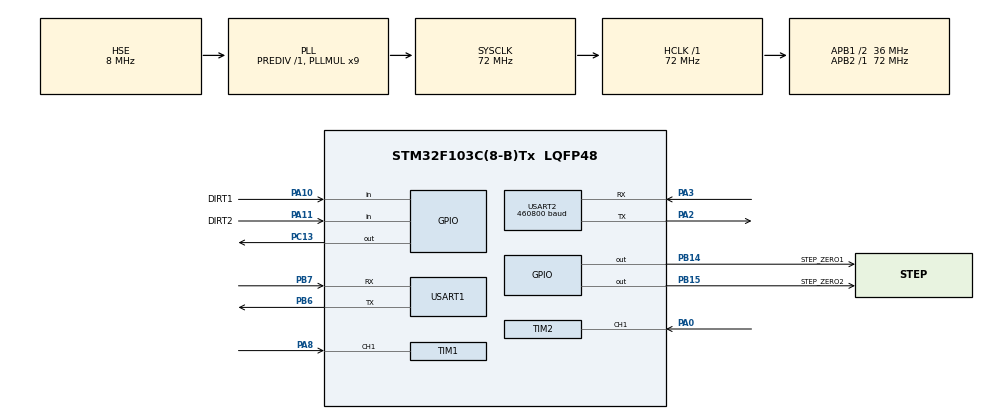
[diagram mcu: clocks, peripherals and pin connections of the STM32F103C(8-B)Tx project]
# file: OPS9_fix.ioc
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FREERTOS.Tasks01=defaultTask,24,128,StartDefaultTask,Default,NULL,Dynamic,NULL,NULL
FREERTOS.configENABLE_FPU=1
Mcu.Family=STM32F1
Mcu.Name=STM32F103C(8-B)Tx
Mcu.Package=LQFP48
NVIC.PriorityGroup=NVIC_PRIORITYGROUP_4
NVIC.TIM4_IRQn=true\:15\:0\:false\:false\:true\:false\:false\:true\:true
NVIC.TimeBase=TIM4_IRQn
NVIC.TimeBaseIP=TIM4
NVIC.USART1_IRQn=true\:5\:0\:false\:false\:true\:true\:true\:true\:true
NVIC.USART2_IRQn=true\:5\:0\:false\:false\:true\:true\:true\:true\:true
PA0-WKUP.Signal=S_TIM2_CH1_ETR
PA10.GPIO_Label=DIRT1
PA10.Signal=GPIO_Input
PA11.GPIO_Label=DIRT2
PA11.Signal=GPIO_Input
PA13.Mode=Serial_Wire
PA13.Signal=SYS_JTMS-SWDIO
PA14.Mode=Serial_Wire
PA14.Signal=SYS_JTCK-SWCLK
PA2.Mode=Asynchronous
PA2.Signal=USART2_TX
PA3.Mode=Asynchronous
PA3.Signal=USART2_RX
PA8.Signal=S_TIM1_CH1
PB14.GPIO_Label=STEP_ZERO1
PB14.Signal=GPIO_Output
PB15.GPIO_Label=STEP_ZERO2
PB15.Signal=GPIO_Output
PB6.Mode=Asynchronous
PB6.Signal=USART1_TX
PB7.Mode=Asynchronous
PB7.Signal=USART1_RX
PC13-TAMPER-RTC.Signal=GPIO_Output
PD0-OSC_IN.Mode=HSE-External-Oscillator
PD0-OSC_IN.Signal=RCC_OSC_IN
PD1-OSC_OUT.Mode=HSE-External-Oscillator
PD1-OSC_OUT.Signal=RCC_OSC_OUT
ProjectManager.HeapSize=0x200
ProjectManager.StackSize=0x400
ProjectManager.TargetToolchain=MDK-ARM V5.32
RCC.AHBFreq_Value=72000000
RCC.APB1CLKDivider=RCC_HCLK_DIV2
RCC.APB1Freq_Value=36000000
RCC.APB1TimFreq_Value=72000000
RCC.APB2Freq_Value=72000000
RCC.APB2TimFreq_Value=72000000
RCC.HCLKFreq_Value=72000000
RCC.PLLMUL=RCC_PLL_MUL9
RCC.PLLSourceVirtual=RCC_PLLSOURCE_HSE
RCC.SYSCLKFreq_VALUE=72000000
RCC.SYSCLKSource=RCC_SYSCLKSOURCE_PLLCLK
RCC.USBFreq_Value=72000000
SH.S_TIM1_CH1.0=TIM1_CH1,TriggerSource_TI1FP1
SH.S_TIM2_CH1_ETR.0=TIM2_CH1,TriggerSource_TI1FP1
USART1.VirtualMode=VM_ASYNC
USART2.BaudRate=460800
USART2.VirtualMode=VM_ASYNC
VP_FREERTOS_VS_CMSIS_V2.Mode=CMSIS_V2
VP_SYS_VS_tim4.Mode=TIM4
VP_TIM1_VS_ControllerModeClock.Mode=Clock Mode
VP_TIM2_VS_ControllerModeClock.Mode=Clock Mode
board=custom

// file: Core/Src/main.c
/* USER CODE BEGIN Header */
/**
  ******************************************************************************
  * @file           : main.c
  * @brief          : Main program body
  ******************************************************************************
  * @attention
  *
  * Copyright (c) 2026 STMicroelectronics.
  * All rights reserved.
  *
  * This software is licensed under terms that can be found in the LICENSE file
  * in the root directory of this software component.
  * If no LICENSE file comes with this software, it is provided AS-IS.
  *
  ******************************************************************************
  */
/* USER CODE END Header */
#include "main.h"
#include "cmsis_os.h"
#include "tim.h"
#include "usart.h"
#include "gpio.h"

/* USER CODE BEGIN Includes */
#include "cyz_gyro.h"
/* USER CODE END Includes */

void SystemClock_Config(void);
void MX_FREERTOS_Init(void);

int main(void)
{

  /* MCU Configuration--------------------------------------------------------*/

  /* Reset of all peripherals, Initializes the Flash interface and the Systick. */
  HAL_Init();

  /* Configure the system clock */
  SystemClock_Config();

  /* Initialize all configured peripherals */
  MX_GPIO_Init();
  MX_TIM1_Init();
  MX_TIM2_Init();
  MX_USART1_UART_Init();
  MX_USART2_UART_Init();
  /* USER CODE BEGIN 2 */
  /* QMM01/CY-Z gyro on USART1: bind the handle and arm byte-wise interrupt
     reception. Runs after MX_USART1_UART_Init() and before the scheduler
     starts, so the module is already reporting once the tasks run. */
  cyz_gyro_init();
  /* USER CODE END 2 */

  /* Init scheduler */
  osKernelInitialize();  /* Call init function for freertos objects (in cmsis_os2.c) */
  MX_FREERTOS_Init();

  /* Start scheduler */
  osKernelStart();

  /* We should never get here as control is now taken by the scheduler */

  /* Infinite loop */
  while (1)
  {

  }
}

void SystemClock_Config(void)
{
  RCC_OscInitTypeDef RCC_OscInitStruct = {0};
  RCC_ClkInitTypeDef RCC_ClkInitStruct = {0};

  /** Initializes the RCC Oscillators according to the specified parameters
  * in the RCC_OscInitTypeDef structure.
  */
  RCC_OscInitStruct.OscillatorType = RCC_OSCILLATORTYPE_HSE;
  RCC_OscInitStruct.HSEState = RCC_HSE_ON;
  RCC_OscInitStruct.HSEPredivValue = RCC_HSE_PREDIV_DIV1;
  RCC_OscInitStruct.HSIState = RCC_HSI_ON;
  RCC_OscInitStruct.PLL.PLLState = RCC_PLL_ON;
  RCC_OscInitStruct.PLL.PLLSource = RCC_PLLSOURCE_HSE;
  RCC_OscInitStruct.PLL.PLLMUL = RCC_PLL_MUL9;
  if (HAL_RCC_OscConfig(&RCC_OscInitStruct) != HAL_OK)
  {
    Error_Handler();
  }

  /** Initializes the CPU, AHB and APB buses clocks
  */
  RCC_ClkInitStruct.ClockType = RCC_CLOCKTYPE_HCLK|RCC_CLOCKTYPE_SYSCLK
                              |RCC_CLOCKTYPE_PCLK1|RCC_CLOCKTYPE_PCLK2;
  RCC_ClkInitStruct.SYSCLKSource = RCC_SYSCLKSOURCE_PLLCLK;
  RCC_ClkInitStruct.AHBCLKDivider = RCC_SYSCLK_DIV1;
  RCC_ClkInitStruct.APB1CLKDivider = RCC_HCLK_DIV2;
  RCC_ClkInitStruct.APB2CLKDivider = RCC_HCLK_DIV1;

  if (HAL_RCC_ClockConfig(&RCC_ClkInitStruct, FLASH_LATENCY_2) != HAL_OK)
  {
    Error_Handler();
  }
}

/* USER CODE BEGIN 4 */
/* Both UARTs share these HAL callbacks, so every event is dispatched on the
   handle: the gyro access layer ignores anything that is not its own USART1
   handle, which leaves the USART2 robot link and its reception untouched. */
void HAL_UART_RxCpltCallback(UART_HandleTypeDef *huart)
{
  cyz_gyro_on_rx_complete(huart);
}

void HAL_UART_ErrorCallback(UART_HandleTypeDef *huart)
{
  cyz_gyro_on_uart_error(huart);
}
/* USER CODE END 4 */

void HAL_TIM_PeriodElapsedCallback(TIM_HandleTypeDef *htim)
{
  if (htim->Instance == TIM4)
  {
    HAL_IncTick();
  }
}

void Error_Handler(void)
{
  __disable_irq();
  while (1)
  {
  }
}

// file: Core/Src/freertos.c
/* USER CODE BEGIN Header */
/**
  ******************************************************************************
  * File Name          : freertos.c
  * Description        : Code for freertos applications
  ******************************************************************************
  * @attention
  *
  * Copyright (c) 2026 STMicroelectronics.
  * All rights reserved.
  *
  * This software is licensed under terms that can be found in the LICENSE file
  * in the root directory of this software component.
  * If no LICENSE file comes with this software, it is provided AS-IS.
  *
  ******************************************************************************
  */
/* USER CODE END Header */

#include "FreeRTOS.h"
#include "task.h"
#include "main.h"
#include "cmsis_os.h"

/* USER CODE BEGIN Includes */
#include "cyz_gyro.h" /* gyro report-rate negotiation + PC13 indicator, polled below */
/* USER CODE END Includes */

/* Definitions for defaultTask */
osThreadId_t defaultTaskHandle;
const osThreadAttr_t defaultTask_attributes = {
  .name = "defaultTask",
  .stack_size = 128 * 4,
  .priority = (osPriority_t) osPriorityNormal,
};

void StartDefaultTask(void *argument);

void MX_FREERTOS_Init(void); /* (MISRA C 2004 rule 8.1) */

void MX_FREERTOS_Init(void) {

  /* Create the thread(s) */
  /* creation of defaultTask */
  defaultTaskHandle = osThreadNew(StartDefaultTask, NULL, &defaultTask_attributes);

}

void StartDefaultTask(void *argument)
{
  /* USER CODE BEGIN StartDefaultTask */
  /* Infinite loop */
  for(;;)
  {
    /* The 1 ms cadence that was already here also carries the gyro layer's two
       periodic jobs, so neither needs a task, a timer or a queue:
       - the report-rate negotiation is a polled state machine: one bounded
         transmit at a time and HAL_GetTick() windows; a module that never
         answers costs it time and nothing else,
       - the PC13 indicator decides its level from the arrival time of the last
         valid frame - the USART1 interrupt never drives a GPIO itself. */
    cyz_gyro_rate_negotiate_poll();
    cyz_gyro_indicator_tick();
    osDelay(1);
  }
  /* USER CODE END StartDefaultTask */
}
